# CRYPTO register map
Vendor: Texas Instruments
Peripheral module from a debugger description file (folder CC26x0R2F).
Registers are 32-bit, read-write, reset 0x0 unless marked. A register's access mark holds for its fields unless they carry their own. Offsets are as the file gives them; lines under a group give offsets from that group; [hi:lo] are bit positions; {n}, {i} and the like mark numbered series; 'fields as' and 'values as' point back to an identical list; <NAME> marks a mode.

## CRYPTO — Crypto core with DMA capability and local key storage
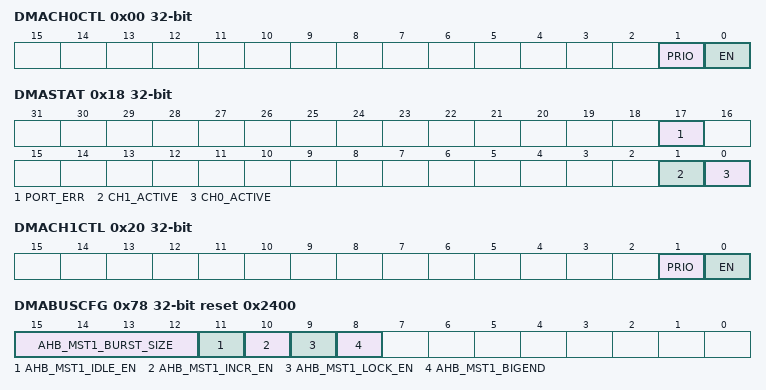
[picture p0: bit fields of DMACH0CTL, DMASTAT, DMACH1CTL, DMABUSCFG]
0x00 DMACH0CTL — DMA Channel 0 Control
  [1] PRIO — Channel priority: A channel with high priority will be served before a channel with low priority in cases with simultaneous access requests. If both channels have the same priority access of the channels to the external port is arbitrated using a Round Robin scheme.
    1=HIGH (Priority high); 0=LOW (Priority low)
  [0] EN — DMA Channel 0 Control
    1=EN (Channel enabled); 0=DIS (Channel disabled)
0x04 DMACH0EXTADDR — DMA Channel 0 External Address
  [31:0] ADDR — Channel external address value. Holds the last updated external address after being sent to the master interface.
0x0C DMACH0LEN — DMA Channel 0 Length
  [15:0] LEN — DMA transfer length in bytes. During configuration, this register contains the DMA transfer length in bytes. During operation, it contains the last updated value of the DMA transfer length after being sent to the master interface. Note: Writing a non-zero value to this register field starts the transfer if the channel is enabled by setting DMACH0CTL.EN.
0x18 DMASTAT ro — DMA Controller Status
  [17] PORT_ERR — Reflects possible transfer errors on the AHB port.
  [1] CH1_ACTIVE — This register field indicates if DMA channel 1 is active or not. 0: Not active 1: Active
  [0] CH0_ACTIVE — This register field indicates if DMA channel 0 is active or not. 0: Not active 1: Active
0x1C DMASWRESET wo — DMA Controller Software Reset
  [0] RESET — Software reset enable 0: Disable 1: Enable (self-cleared to zero). Note: Completion of the software reset must be checked in DMASTAT.CH0_ACTIVE and DMASTAT.CH1_ACTIVE.
0x20 DMACH1CTL — DMA Channel 1 Control
  [1] PRIO — Channel priority: A channel with high priority will be served before a channel with low priority in cases with simultaneous access requests. If both channels have the same priority access of the channels to the external port is arbitrated using a Round Robin scheme.
    1=HIGH (Priority high); 0=LOW (Priority low)
  [0] EN — Channel enable: Note: Disabling an active channel will interrupt the DMA operation. The ongoing block transfer will be completed, but no new transfers will be requested.
    1=EN (Channel enabled); 0=DIS (Channel disabled)
0x24 DMACH1EXTADDR — DMA Channel 1 External Address
  fields as DMACH0EXTADDR
0x2C DMACH1LEN — DMA Channel 1 Length
  [15:0] LEN — DMA transfer length in bytes. During configuration, this register contains the DMA transfer length in bytes. During operation, it contains the last updated value of the DMA transfer length after being sent to the master interface. Note: Writing a non-zero value to this register field starts the transfer if the channel is enabled by setting DMACH1CTL.EN.
0x78 DMABUSCFG reset 0x2400 — DMA Controller Master Configuration
  [15:12] AHB_MST1_BURST_SIZE — Maximum burst size that can be performed on the AHB bus
    6=64_BYTE (64 bytes); 5=32_BYTE (32 bytes); 4=16_BYTE (16 bytes); 3=8_BYTE (8 bytes); 2=4_BYTE (4 bytes)
  [11] AHB_MST1_IDLE_EN — Idle transfer insertion between consecutive burst transfers on AHB
    1=IDLE (Idle transfer insertion enabled); 0=NO_IDLE (Do not insert idle transfers.)
  [10] AHB_MST1_INCR_EN — Burst length type of AHB transfer
    1=SPECIFIED (Fixed length bursts or single transfers); 0=UNSPECIFIED (Unspecified length burst transfers)
  [9] AHB_MST1_LOCK_EN — Locked transform on AHB
    1=LOCKED (Transfers are locked); 0=NOT_LOCKED (Transfers are not locked)
  [8] AHB_MST1_BIGEND — Endianess for the AHB master
    1=BIG_ENDIAN; 0=LITTLE_ENDIAN
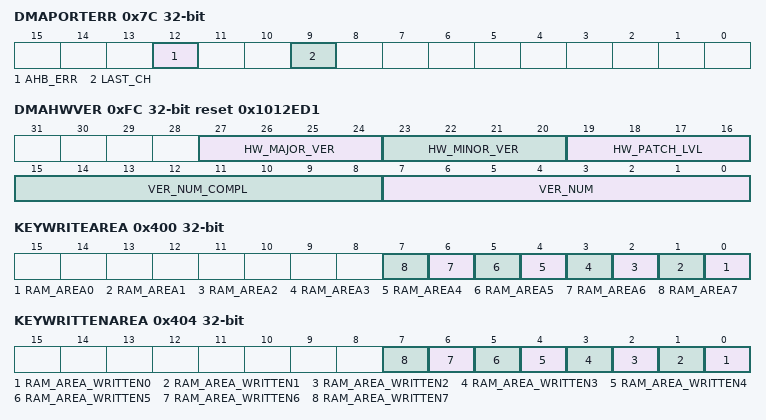
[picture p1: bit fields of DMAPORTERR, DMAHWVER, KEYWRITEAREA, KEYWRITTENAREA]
0x7C DMAPORTERR ro — DMA Controller Port Error
  [12] AHB_ERR — A 1 indicates that the Crypto peripheral has detected an AHB bus error
  [9] LAST_CH — Indicates which channel was serviced last (channel 0 or channel 1) by the AHB master port.
0xFC DMAHWVER ro reset 0x1012ED1 — DMA Controller Version
  [27:24] HW_MAJOR_VER — Major version number
  [23:20] HW_MINOR_VER — Minor version number
  [19:16] HW_PATCH_LVL — Patch level.
  [15:8] VER_NUM_COMPL — Bit-by-bit complement of the VER_NUM field bits.
  [7:0] VER_NUM — Version number of the DMA Controller (209)
0x400 KEYWRITEAREA
  [all] fields
    1=SEL (This RAM area is selected to be written); 0=NOT_SEL (This RAM area is not selected to be written)
  [n] RAM_AREA{n} (n=0..7) — Represents an area of 128 bits. Select the key store RAM area(s) where the key(s) needs to be written. Writing to multiple RAM locations is only possible when the selected RAM areas are sequential.
0x404 KEYWRITTENAREA — Key Written Area Status This register shows which areas of the key store RAM contain valid written keys. When a new key needs to be written to the key store, on a location that is already occupied by a valid key, this key area must be cleared first. This can be done by writing this register before the new key is written to the key store memory. Attempting to write to a key area that already contains a valid key is not allowed and will result in an error.
  [all] fields
    1=WRITTEN (This RAM area is written with valid key information); 0=NOT_WRITTEN (This RAM area is not written with valid key information)
  [n] RAM_AREA_WRITTEN{n} (n=0..7) — On read this bit returns the key area written status. This bit can be reset by writing a 1. Note: This register will be reset on a soft reset initiated by writing to DMASWRESET.RESET. After a soft reset, all keys must be rewritten to the key store memory.
0x408 KEYSIZE reset 0x1 — Key Size This register defines the size of the keys that are written with DMA.
  [1:0] SIZE — Key size When writing to this register, KEYWRITTENAREA will be reset. Note: For the Crypto peripheral this field is fixed to 128 bits. For software compatibility KEYWRITTENAREA will be reset when writing to this register.
    3=256_BIT (Not supported); 2=192_BIT (Not supported); 1=128_BIT (128 bits)
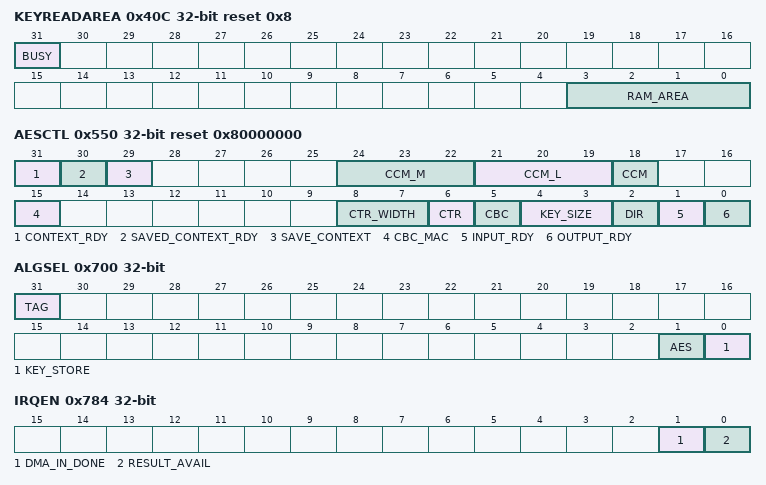
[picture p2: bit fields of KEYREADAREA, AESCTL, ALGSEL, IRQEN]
0x40C KEYREADAREA access per field reset 0x8
  [31] BUSY ro — Key store operation busy status flag (read only) 0: operation is completed. 1: operation is not completed and the key store is busy.
  [3:0] RAM_AREA rw — Selects the area of the key store RAM from where the key needs to be read that will be written to the AES engine. Only RAM areas that contain valid written keys can be selected.
    8=NO_RAM; {v}=RAM_AREA{v} (v=0..7)
0x500 AESKEY2 wo — Clear AES_KEY2/GHASH Key
  [31:0] KEY2 — AESKEY2.* bits 31+x:0+x or AES_GHASH_H.* bits 31+x:0+x, where x = 0, 32, 64, 96 ordered from the LSW entry of this 4-deep register array. The interpretation of this field depends on the crypto operation mode.
0x510 AESKEY3 wo — Clear AES_KEY3
  [31:0] KEY3 — AESKEY3.* bits 31+x:0+x or AESKEY2.* bits 159+x:128+x, where x = 0, 32, 64, 96 ordered from the LSW entry of this 4-deep register arrary. The interpretation of this field depends on the crypto operation mode.
0x540 AESIV — AES Initialization Vector
  [31:0] IV — The interpretation of this field depends on the crypto operation mode.
0x550 AESCTL access per field reset 0x80000000 — AES Input/Output Buffer Control
  [31] CONTEXT_RDY ro — If 1, this status bit indicates that the context data registers can be overwritten and the Host is permitted to write the next context. Writing a context means writing either a mode, the crypto length or AESDATALEN1.LEN_MSW, AESDATALEN0.LEN_LSW length registers
  [30] SAVED_CONTEXT_RDY rw — If read as 1, this status bit indicates that an AES authentication TAG and/or IV block(s) is/are available for the Host to retrieve. This bit is only asserted if SAVE_CONTEXT is set to 1. The bit is mutually exclusive with CONTEXT_RDY. Writing 1 clears the bit to zero, indicating the Crypto peripheral can start its next operation. This bit is also cleared when the 4th word of the output TAG and/or IV is read. Note: All other mode bit writes will be ignored when this mode bit is written with 1. Note: This bit is controlled automatically by the Crypto peripheral for TAG read DMA operations. For typical use, this bit does NOT need to be written, but is used for status reading only. In this case, this status bit is automatically maintained by the Crypto peripheral.
  [29] SAVE_CONTEXT rw — IV must be read before the AES engine can start a new operation.
  [24:22] CCM_M rw — Defines M that indicates the length of the authentication field for CCM operations; the authentication field length equals two times the value of CCM_M plus one. Note: The Crypto peripheral always returns a 128-bit authentication field, of which the M least significant bytes are valid. All values are supported.
  [21:19] CCM_L rw — Defines L that indicates the width of the length field for CCM operations; the length field in bytes equals the value of CMM_L plus one. All values are supported.
  [18] CCM rw — AES-CCM mode enable. AES-CCM is a combined mode, using AES for both authentication and encryption. Note: Selecting AES-CCM mode requires writing of AESDATALEN1.LEN_MSW and AESDATALEN0.LEN_LSW after all other registers. Note: The CTR mode bit in this register must also be set to 1 to enable AES-CTR; selecting other AES modes than CTR mode is invalid.
  [15] CBC_MAC rw — MAC mode enable. The DIR bit must be set to 1 for this mode. Selecting this mode requires writing the AESDATALEN1.LEN_MSW and AESDATALEN0.LEN_LSW registers after all other registers.
  [8:7] CTR_WIDTH rw — Specifies the counter width for AES-CTR mode
    3=128_BIT (128 bits); 2=96_BIT (96 bits); 1=64_BIT (64 bits); 0=32_BIT (32 bits)
  [6] CTR rw — AES-CTR mode enable This bit must also be set for CCM, when encryption/decryption is required.
  [5] CBC rw — CBC mode enable
  [4:3] KEY_SIZE ro — This field specifies the key size. The key size is automatically configured when a new key is loaded via the key store module. 00 = N/A - reserved 01 = 128 bits 10 = N/A - reserved 11 = N/A - reserved For the Crypto peripheral this field is fixed to 128 bits.
  [2] DIR rw — Direction. 0 : Decrypt operation is performed. 1 : Encrypt operation is performed. This bit must be written with a 1 when CBC-MAC is selected.
  [1] INPUT_RDY rw — If read as 1, this status bit indicates that the 16-byte AES input buffer is empty. The Host is permitted to write the next block of data. Writing a 0 clears the bit to zero and indicates that the AES engine can use the provided input data block. Writing a 1 to this bit will be ignored. Note: For DMA operations, this bit is automatically controlled by the Crypto peripheral. After reset, this bit is 0. After writing a context (note 1), this bit will become 1. For typical use, this bit does NOT need to be written, but is used for status reading only. In this case, this status bit is automatically maintained by the Crypto peripheral.
  [0] OUTPUT_RDY rw — If read as 1, this status bit indicates that an AES output block is available to be retrieved by the Host. Writing a 0 clears the bit to zero and indicates that output data is read by the Host. The AES engine can provide a next output data block. Writing a 1 to this bit will be ignored. Note: For DMA operations, this bit is automatically controlled by the Crypto peripheral. For typical use, this bit does NOT need to be written, but is used for status reading only. In this case, this status bit is automatically maintained by the Crypto peripheral.
0x554 AESDATALEN0 wo — Crypto Data Length LSW
  [31:0] LEN_LSW — Used to write the Length values to the Crypto peripheral. This register contains bits [31:0] of the combined data length.
0x558 AESDATALEN1 wo — Crypto Data Length MSW
  [28:0] LEN_MSW — Bits [60:32] of the combined data length. Bits [60:0] of the crypto length registers AESDATALEN1 and AESDATALEN0 store the cryptographic data length in bytes for all modes. Once processing with this context is started, this length decrements to zero. Data lengths up to (2^61 - 1) bytes are allowed. For GCM, any value up to 2^36 - 32 bytes can be used. This is because a 32-bit counter mode is used; the maximum number of 128-bit blocks is 2^32 - 2, resulting in a maximum number of bytes of 2^36 - 32. Writing to this register triggers the engine to start using this context. This is valid for all modes except GCM and CCM. Note: For the combined modes (GCM and CCM), this length does not include the authentication only data; the authentication length is specified in the AESAUTHLEN.LEN. All modes must have a length > 0. For the combined modes, it is allowed to have one of the lengths equal to zero. For the basic encryption modes (ECB/CBC/CTR) it is allowed to program zero to the length field; in that case the length is assumed infinite. All data must be byte (8-bit) aligned for stream cipher modes; bit aligned data streams are not supported by the Crypto peripheral. For block cipher modes, the data length must be programmed in multiples of the block cipher size, 16 bytes.
0x55C AESAUTHLEN wo — AES Authentication Length
  [31:0] LEN — Authentication data length in bytes for combined mode, CCM only. Supported AAD-lengths for CCM are from 0 to (216 - 28) bytes. Once processing with this context is started, this length decrements to zero. Writing this register triggers the engine to start using this context for CCM.
0x560 AESDATAOUT0 ro — Data Input/Output
  [31:0] DATA — Data register 0 for output block data from the Crypto peripheral. These bits = AES Output Data[31:0] of {127:0] For normal operations, this register is not used, since data input and output is transferred from and to the AES engine via DMA. For a Host read operation, these registers contain the 128-bit output block from the latest AES operation. Reading from a word-aligned offset within this address range will read one word (4 bytes) of data out the 4-word deep (16 bytes = 128-bits AES block) data output buffer. The words (4 words, one full block) should be read before the core will move the next block to the data output buffer. To empty the data output buffer, AESCTL.OUTPUT_RDY must be written. For the modes with authentication (CBC-MAC, GCM and CCM), the invalid (message) bytes/words can be written with any data. Note: The AAD / authentication only data is not copied to the output buffer but only used for authentication.
{0x560+4i} AESDATAIN{i} wo (i=0..2) — AES Data Input/Output {i}
  [31:0] DATA — Data registers for input block data to the Crypto peripheral. These bits = AES Input Data[{32i+31}:{32i}] of [127:0] For normal operations, this register is not used, since data input and output is transferred from and to the AES engine via DMA. For a Host write operation, these registers must be written with the 128-bit input block for the next AES operation. Writing at a word-aligned offset within this address range will store the word (4 bytes) of data into the corresponding position of 4-word deep (16 bytes = 128-bit AES block) data input buffer. This buffer is used for the next AES operation. If the last data block is not completely filled with valid data (see notes below), it is allowed to write only the words with valid data. Next AES operation is triggered by writing to AESCTL.INPUT_RDY. Note: AES typically operates on 128 bits block multiple input data. The CTR, GCM and CCM modes form an exception. The last block of a CTR-mode message may contain less than 128 bits (refer to [NIST 800-38A]): 0 < n <= 128 bits. For GCM/CCM, the last block of both AAD and message data may contain less than 128 bits (refer to [NIST 800-38D]). The Crypto peripheral automatically pads or masks misaligned ending data blocks with zeroes for GCM, CCM and CBC-MAC. For CTR mode, the remaining data in an unaligned data block is ignored.
0x564 AESDATAOUT1 ro — AES Data Input/Output 3
  [31:0] DATA — Data registers for output block data from the Crypto peripheral. These bits = AES Output Data[63:32] of [127:0] For normal operations, this register is not used, since data input and output is transferred from and to the AES engine via DMA. For a Host read operation, these registers contain the 128-bit output block from the latest AES operation. Reading from a word-aligned offset within this address range will read one word (4 bytes) of data out the 4-word deep (16 bytes = 128-bits AES block) data output buffer. The words (4 words, one full block) should be read before the core will move the next block to the data output buffer. To empty the data output buffer, AESCTL.OUTPUT_RDY must be written. For the modes with authentication (CBC-MAC, GCM and CCM), the invalid (message) bytes/words can be written with any data. Note: The AAD / authentication only data is not copied to the output buffer but only used for authentication.
0x568 AESDATAOUT2 ro — AES Data Input/Output 2
  [31:0] DATA — Data registers for output block data from the Crypto peripheral. These bits = AES Output Data[95:64] of [127:0] For normal operations, this register is not used, since data input and output is transferred from and to the AES engine via DMA. For a Host read operation, these registers contain the 128-bit output block from the latest AES operation. Reading from a word-aligned offset within this address range will read one word (4 bytes) of data out the 4-word deep (16 bytes = 128-bits AES block) data output buffer. The words (4 words, one full block) should be read before the core will move the next block to the data output buffer. To empty the data output buffer, AESCTL.OUTPUT_RDY must be written. For the modes with authentication (CBC-MAC, GCM and CCM), the invalid (message) bytes/words can be written with any data. Note: The AAD / authentication only data is not copied to the output buffer but only used for authentication.
0x56C AESDATAOUT3 ro — AES Data Input/Output 3
  [31:0] DATA — Data registers for output block data from the Crypto peripheral. These bits = AES Output Data[127:96] of [127:0] For normal operations, this register is not used, since data input and output is transferred from and to the AES engine via DMA. For a Host read operation, these registers contain the 128-bit output block from the latest AES operation. Reading from a word-aligned offset within this address range will read one word (4 bytes) of data out the 4-word deep (16 bytes = 128-bits AES block) data output buffer. The words (4 words, one full block) should be read before the core will move the next block to the data output buffer. To empty the data output buffer, AESCTL.OUTPUT_RDY must be written. For the modes with authentication (CBC-MAC, GCM and CCM), the invalid (message) bytes/words can be written with any data. Note: The AAD / authentication only data is not copied to the output buffer but only used for authentication.
0x56C AESDATAIN3 wo — Data Input/Output
  [31:0] DATA — Data registers for input block data to the Crypto peripheral. These bits = AES Input Data[127:96] of [127:0] For normal operations, this register is not used, since data input and output is transferred from and to the AES engine via DMA. For a Host write operation, these registers must be written with the 128-bit input block for the next AES operation. Writing at a word-aligned offset within this address range will store the word (4 bytes) of data into the corresponding position of 4-word deep (16 bytes = 128-bit AES block) data input buffer. This buffer is used for the next AES operation. If the last data block is not completely filled with valid data (see notes below), it is allowed to write only the words with valid data. Next AES operation is triggered by writing to AESCTL.INPUT_RDY. Note: AES typically operates on 128 bits block multiple input data. The CTR, GCM and CCM modes form an exception. The last block of a CTR-mode message may contain less than 128 bits (refer to [NIST 800-38A]): 0 < n <= 128 bits. For GCM/CCM, the last block of both AAD and message data may contain less than 128 bits (refer to [NIST 800-38D]). The Crypto peripheral automatically pads or masks misaligned ending data blocks with zeroes for GCM, CCM and CBC-MAC. For CTR mode, the remaining data in an unaligned data block is ignored.
0x570 AESTAGOUT ro — AES Tag Output
  [31:0] TAG — This register contains the authentication TAG for the combined and authentication-only modes.
0x700 ALGSEL — Master Algorithm Select This register configures the internal destination of the DMA controller.
  [31] TAG — If this bit is cleared to 0, the DMA operation involves only data. If this bit is set, the DMA operation includes a TAG (Authentication Result / Digest).
  [1] AES — If set to 1, the AES data is loaded via DMA Both Read and Write maximum transfer size to DMA engine is set to 16 bytes
  [0] KEY_STORE — If set to 1, selects the Key Store to be loaded via DMA. The maximum transfer size to DMA engine is set to 32 bytes (however transfers of 16, 24 and 32 bytes are allowed)
0x704 DMAPROTCTL — Master Protection Control
  [0] EN — Select AHB transfer protection control for DMA transfers using the key store area as destination. 0 : transfers use 'USER' type access. 1 : transfers use 'PRIVILEGED' type access.
0x740 SWRESET — Software Reset
  [0] RESET — If this bit is set to 1, the following modules are reset: - Master control internal state is reset. That includes interrupt, error status register and result available interrupt generation FSM. - Key store module state is reset. That includes clearing the Written Area flags; therefore the keys must be reloaded to the key store module. Writing 0 has no effect. The bit is self cleared after executing the reset.
0x780 IRQTYPE — Control Interrupt Configuration
  [0] LEVEL — If this bit is 0, the interrupt output is a pulse. If this bit is set to 1, the interrupt is a level interrupt that must be cleared by writing the interrupt clear register. This bit is applicable for both interrupt output signals.
0x784 IRQEN — Interrupt Enable
  [1] DMA_IN_DONE — This bit enables IRQSTAT.DMA_IN_DONE as source for IRQ.
  [0] RESULT_AVAIL — This bit enables IRQSTAT.RESULT_AVAIL as source for IRQ.
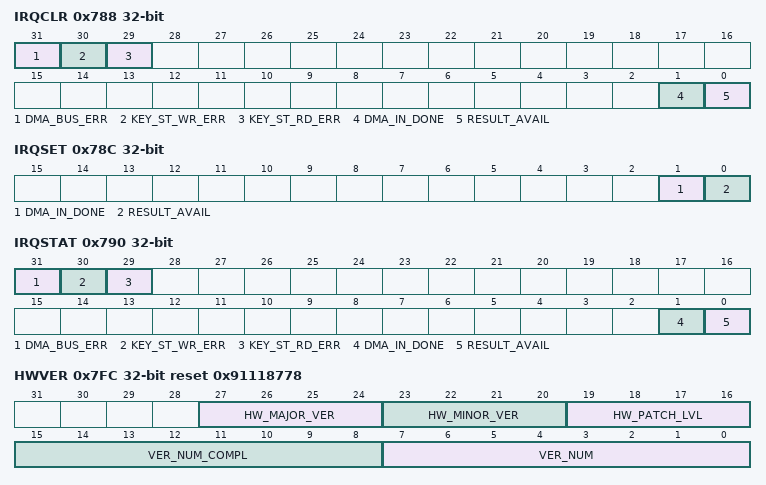
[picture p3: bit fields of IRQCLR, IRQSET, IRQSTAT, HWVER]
0x788 IRQCLR wo — Interrupt Clear
  [31] DMA_BUS_ERR — If 1 is written to this bit, IRQSTAT.DMA_BUS_ERR is cleared.
  [30] KEY_ST_WR_ERR — If 1 is written to this bit, IRQSTAT.KEY_ST_WR_ERR is cleared.
  [29] KEY_ST_RD_ERR — If 1 is written to this bit, IRQSTAT.KEY_ST_RD_ERR is cleared.
  [1] DMA_IN_DONE — If 1 is written to this bit, IRQSTAT.DMA_IN_DONE is cleared.
  [0] RESULT_AVAIL — If 1 is written to this bit, IRQSTAT.RESULT_AVAIL is cleared.
0x78C IRQSET wo — Interrupt Set
  [1] DMA_IN_DONE — If 1 is written to this bit, IRQSTAT.DMA_IN_DONE is set. Writing 0 has no effect.
  [0] RESULT_AVAIL — If 1 is written to this bit, IRQSTAT.RESULT_AVAIL is set. Writing 0 has no effect.
0x790 IRQSTAT ro — Interrupt Status
  [31] DMA_BUS_ERR — This bit is set when a DMA bus error is detected during a DMA operation. The value of this register is held until it is cleared via IRQCLR.DMA_BUS_ERR Note: This error is asserted if an error is detected on the AHB master interface during a DMA operation. Note: This is not an interrupt source.
  [30] KEY_ST_WR_ERR — This bit is set when a write error is detected during the DMA write operation to the key store memory. The value of this register is held until it is cleared via IRQCLR.KEY_ST_WR_ERR Note: This error is asserted if a DMA operation does not cover a full key area or more areas are written than expected. Note: This is not an interrupt source.
  [29] KEY_ST_RD_ERR — This bit will be set when a read error is detected during the read of a key from the key store, while copying it to the AES engine. The value of this register is held until it is cleared via IRQCLR.KEY_ST_RD_ERR. Note: This error is asserted if a key location is selected in the key store that is not available. Note: This is not an interrupt source.
  [1] DMA_IN_DONE — This bit returns the status of DMA data in done interrupt.
  [0] RESULT_AVAIL — This bit is set high when the Crypto peripheral has a result available.
0x7FC HWVER ro reset 0x91118778 — CTRL Module Version
  [27:24] HW_MAJOR_VER — Major version number
  [23:20] HW_MINOR_VER — Minor version number
  [19:16] HW_PATCH_LVL — Patch level, starts at 0 at first delivery of this version.
  [15:8] VER_NUM_COMPL — These bits simply contain the complement of VER_NUM (0x87), used by a driver to ascertain that the Crypto peripheral register is indeed read.
  [7:0] VER_NUM — The version number for the Crypto peripheral, this field contains the value 120 (decimal) or 0x78.
